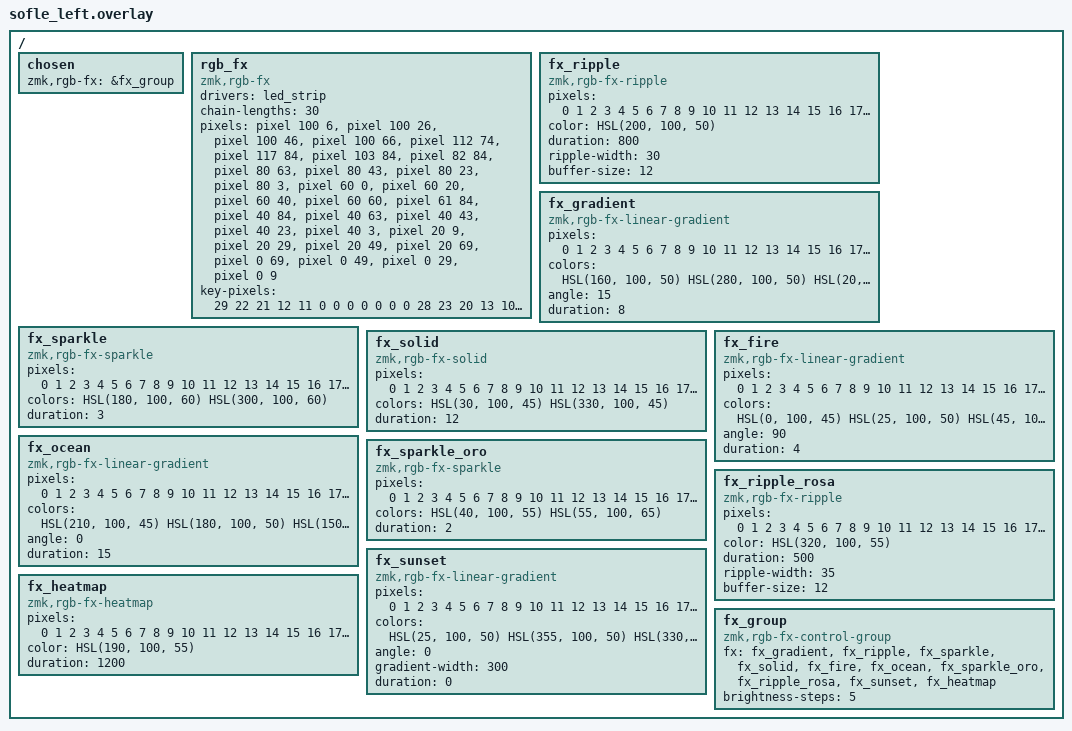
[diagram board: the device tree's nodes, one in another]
/*
 * RGB FX - mitad izquierda.
 *
 * pixels: coordenadas (x,y) de cada LED en ORDEN DE CADENA (foto del PCB):
 * la cadena empieza en la columna interior (arriba->abajo), recorre los
 * pulgares y serpentea por columnas hasta la pinky. x crece hacia el interior
 * en unidades ~ paso de tecla / 20.
 *
 * key-pixels: indice de pixel para cada una de las 60 posiciones del matrix
 * transform del Sofle. Las posiciones de la OTRA mitad apuntan al pixel del
 * borde interior de su fila: el ripple de teclas remotas entra por el borde.
 */

#include <rgb_fx.dtsi>
#include <dt-bindings/zmk/rgb_fx.h>

/ {
    chosen {
        zmk,rgb-fx = &fx_group;
    };

    rgb_fx: rgb_fx {
        compatible = "zmk,rgb-fx";
        drivers = <&led_strip>;
        chain-lengths = <30>;
        pixels
            = <&pixel 100 6>,  /* 0  col interior fila0 (cadena empieza arriba) */
              <&pixel 100 26>, /* 1  */
              <&pixel 100 46>, /* 2  */
              <&pixel 100 66>, /* 3  */
              <&pixel 112 74>, /* 4  LED del encoder (5o de la cadena) */
              <&pixel 117 84>, /* 5  pulgar interior */
              <&pixel 103 84>, /* 6  */
              <&pixel 82 84>,  /* 7  */
              <&pixel 80 63>,  /* 8  col 4 fila3 */
              <&pixel 80 43>,  /* 9  */
              <&pixel 80 23>,  /* 10 */
              <&pixel 80 3>,   /* 11 col 4 fila0 */
              <&pixel 60 0>,   /* 12 col 3 fila0 */
              <&pixel 60 20>,  /* 13 */
              <&pixel 60 40>,  /* 14 */
              <&pixel 60 60>,  /* 15 col 3 fila3 */
              <&pixel 61 84>,  /* 16 pulgar */
              <&pixel 40 84>,  /* 17 pulgar exterior */
              <&pixel 40 63>,  /* 18 col 2 fila3 */
              <&pixel 40 43>,  /* 19 */
              <&pixel 40 23>,  /* 20 */
              <&pixel 40 3>,   /* 21 col 2 fila0 */
              <&pixel 20 9>,   /* 22 col 1 fila0 */
              <&pixel 20 29>,  /* 23 */
              <&pixel 20 49>,  /* 24 */
              <&pixel 20 69>,  /* 25 col 1 fila3 */
              <&pixel 0 69>,   /* 26 pinky fila3 */
              <&pixel 0 49>,   /* 27 */
              <&pixel 0 29>,   /* 28 */
              <&pixel 0 9>;    /* 29 pinky fila0 */
        key-pixels
            = <29 22 21 12 11 0 0 0 0 0 0 0
               28 23 20 13 10 1 1 1 1 1 1 1
               27 24 19 14 9 2 2 2 2 2 2 2
               26 25 18 15 8 3 4 3 3 3 3 3 3 3
               17 16 7 6 5 5 5 5 5 5>;
    };

    fx_ripple: fx_ripple {
        compatible = "zmk,rgb-fx-ripple";
        pixels = <0 1 2 3 4 5 6 7 8 9 10 11 12 13 14 15 16 17 18 19 20 21 22 23 24 25 26 27 28 29>;
        color = <HSL(200, 100, 50)>;
        duration = <800>;
        ripple-width = <30>;
        buffer-size = <12>;
    };

    fx_gradient: fx_gradient {
        compatible = "zmk,rgb-fx-linear-gradient";
        pixels = <0 1 2 3 4 5 6 7 8 9 10 11 12 13 14 15 16 17 18 19 20 21 22 23 24 25 26 27 28 29>;
        colors = <HSL(160, 100, 50) HSL(280, 100, 50) HSL(20, 100, 50)>;
        angle = <15>;
        duration = <8>;
    };

    fx_sparkle: fx_sparkle {
        compatible = "zmk,rgb-fx-sparkle";
        pixels = <0 1 2 3 4 5 6 7 8 9 10 11 12 13 14 15 16 17 18 19 20 21 22 23 24 25 26 27 28 29>;
        colors = <HSL(180, 100, 60) HSL(300, 100, 60)>;
        duration = <3>;
    };

    fx_solid: fx_solid {
        compatible = "zmk,rgb-fx-solid";
        pixels = <0 1 2 3 4 5 6 7 8 9 10 11 12 13 14 15 16 17 18 19 20 21 22 23 24 25 26 27 28 29>;
        colors = <HSL(30, 100, 45) HSL(330, 100, 45)>;
        duration = <12>;
    };


    /* --- Modos extra: mismo motor, distintas paletas/velocidades ---
     * velocidad = duration (menor = mas rapido) | tono = colors HSL(h,s,l) */

    fx_fire: fx_fire {
        compatible = "zmk,rgb-fx-linear-gradient";
        pixels = <0 1 2 3 4 5 6 7 8 9 10 11 12 13 14 15 16 17 18 19 20 21 22 23 24 25 26 27 28 29>;
        colors = <HSL(0, 100, 45) HSL(25, 100, 50) HSL(45, 100, 55)>;
        angle = <90>;
        duration = <4>;
    };

    fx_ocean: fx_ocean {
        compatible = "zmk,rgb-fx-linear-gradient";
        pixels = <0 1 2 3 4 5 6 7 8 9 10 11 12 13 14 15 16 17 18 19 20 21 22 23 24 25 26 27 28 29>;
        colors = <HSL(210, 100, 45) HSL(180, 100, 50) HSL(150, 90, 45)>;
        angle = <0>;
        duration = <15>;
    };


    fx_sparkle_oro: fx_sparkle_oro {
        compatible = "zmk,rgb-fx-sparkle";
        pixels = <0 1 2 3 4 5 6 7 8 9 10 11 12 13 14 15 16 17 18 19 20 21 22 23 24 25 26 27 28 29>;
        colors = <HSL(40, 100, 55) HSL(55, 100, 65)>;
        duration = <2>;
    };

    fx_ripple_rosa: fx_ripple_rosa {
        compatible = "zmk,rgb-fx-ripple";
        pixels = <0 1 2 3 4 5 6 7 8 9 10 11 12 13 14 15 16 17 18 19 20 21 22 23 24 25 26 27 28 29>;
        color = <HSL(320, 100, 55)>;
        duration = <500>;
        ripple-width = <35>;
        buffer-size = <12>;
    };


    /* Degradado ESTATICO: naranja-coral-rosa-morado-azul, saturacion
     * maxima. duration 0 = fijo; el tono se rota con lower+F/G o el
     * encoder derecho en lower. */
    fx_sunset: fx_sunset {
        compatible = "zmk,rgb-fx-linear-gradient";
        pixels = <0 1 2 3 4 5 6 7 8 9 10 11 12 13 14 15 16 17 18 19 20 21 22 23 24 25 26 27 28 29>;
        colors = <HSL(25, 100, 50) HSL(355, 100, 50) HSL(330, 100, 50)
                  HSL(285, 100, 50) HSL(235, 100, 50)>;
        angle = <0>;
        /* 5 paradas = 4 segmentos iguales; ancho 300 con teclado de 240
         * muestra el arco completo sin que el ciclo se repita. El coral
         * (355) fuerza mas tonos visibles en el tramo naranja->rosa, que
         * cruza la banda perceptualmente plana del rojo. */
        gradient-width = <300>;
        duration = <0>;
    };


    fx_heatmap: fx_heatmap {
        compatible = "zmk,rgb-fx-heatmap";
        pixels = <0 1 2 3 4 5 6 7 8 9 10 11 12 13 14 15 16 17 18 19 20 21 22 23 24 25 26 27 28 29>;
        color = <HSL(190, 100, 55)>;
        duration = <1200>;
    };

    fx_group: fx_group {
        compatible = "zmk,rgb-fx-control-group";
        fx = <&fx_gradient &fx_ripple &fx_sparkle &fx_solid
              &fx_fire &fx_ocean &fx_sparkle_oro &fx_ripple_rosa
              &fx_sunset &fx_heatmap>;
        brightness-steps = <5>;
    };
};
